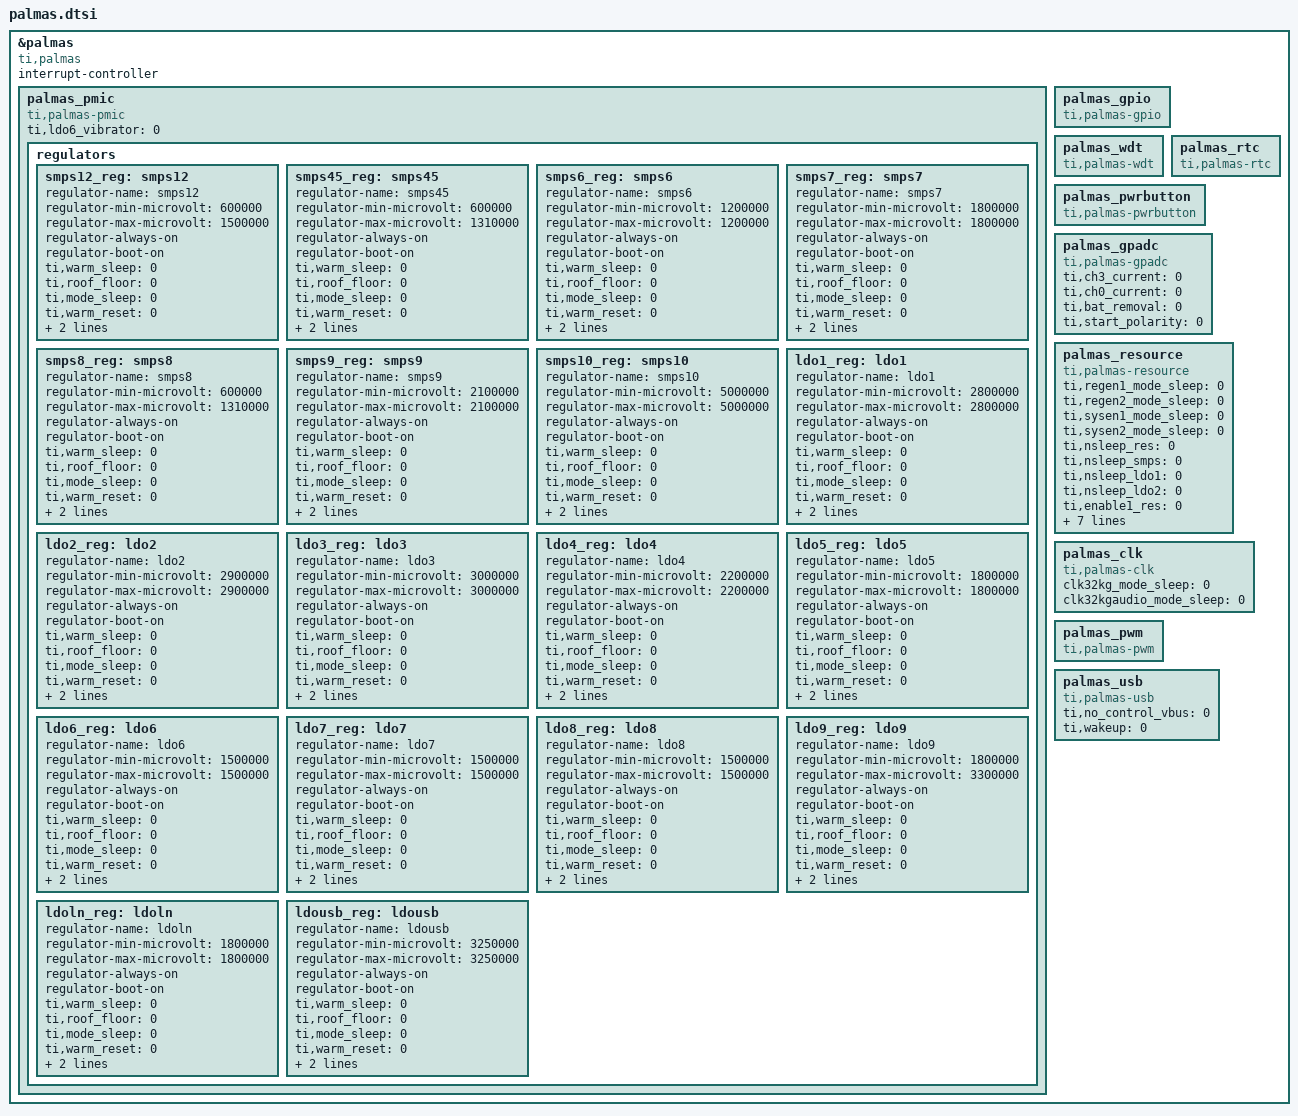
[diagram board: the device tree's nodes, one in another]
&palmas {
	compatible = "ti,palmas";
	interrupt-controller;
	#interrupt-cells = <2>;

	palmas_pmic {
		compatible = "ti,palmas-pmic";
		ti,ldo6_vibrator = <0>;

		regulators {
			smps12_reg: smps12 {
				regulator-name = "smps12";
				regulator-min-microvolt = < 600000>;
				regulator-max-microvolt = <1500000>;
				regulator-always-on;
				regulator-boot-on;
				ti,warm_sleep = <0>;
				ti,roof_floor = <0>;
				ti,mode_sleep = <0>;
				ti,warm_reset = <0>;
				ti,tstep = <0>;
				ti,vsel = <0>;
			};

			smps45_reg: smps45 {
				regulator-name = "smps45";
				regulator-min-microvolt = < 600000>;
				regulator-max-microvolt = <1310000>;
				regulator-always-on;
				regulator-boot-on;
				ti,warm_sleep = <0>;
				ti,roof_floor = <0>;
				ti,mode_sleep = <0>;
				ti,warm_reset = <0>;
				ti,tstep = <0>;
				ti,vsel = <0>;
			};

			smps6_reg: smps6 {
				regulator-name = "smps6";
				regulator-min-microvolt = <1200000>;
				regulator-max-microvolt = <1200000>;
				regulator-always-on;
				regulator-boot-on;
				ti,warm_sleep = <0>;
				ti,roof_floor = <0>;
				ti,mode_sleep = <0>;
				ti,warm_reset = <0>;
				ti,tstep = <0>;
				ti,vsel = <0>;
			};

			smps7_reg: smps7 {
				regulator-name = "smps7";
				regulator-min-microvolt = <1800000>;
				regulator-max-microvolt = <1800000>;
				regulator-always-on;
				regulator-boot-on;
				ti,warm_sleep = <0>;
				ti,roof_floor = <0>;
				ti,mode_sleep = <0>;
				ti,warm_reset = <0>;
				ti,tstep = <0>;
				ti,vsel = <0>;
			};

			smps8_reg: smps8 {
				regulator-name = "smps8";
				regulator-min-microvolt = < 600000>;
				regulator-max-microvolt = <1310000>;
				regulator-always-on;
				regulator-boot-on;
				ti,warm_sleep = <0>;
				ti,roof_floor = <0>;
				ti,mode_sleep = <0>;
				ti,warm_reset = <0>;
				ti,tstep = <0>;
				ti,vsel = <0>;
			};

			smps9_reg: smps9 {
				regulator-name = "smps9";
				regulator-min-microvolt = <2100000>;
				regulator-max-microvolt = <2100000>;
				regulator-always-on;
				regulator-boot-on;
				ti,warm_sleep = <0>;
				ti,roof_floor = <0>;
				ti,mode_sleep = <0>;
				ti,warm_reset = <0>;
				ti,tstep = <0>;
				ti,vsel = <0x80>;
			};

			smps10_reg: smps10 {
				regulator-name = "smps10";
				regulator-min-microvolt = <5000000>;
				regulator-max-microvolt = <5000000>;
				regulator-always-on;
				regulator-boot-on;
				ti,warm_sleep = <0>;
				ti,roof_floor = <0>;
				ti,mode_sleep = <0>;
				ti,warm_reset = <0>;
				ti,tstep = <0>;
				ti,vsel = <0>;
			};

			ldo1_reg: ldo1 {
				regulator-name = "ldo1";
				regulator-min-microvolt = <2800000>;
				regulator-max-microvolt = <2800000>;
				regulator-always-on;
				regulator-boot-on;
				ti,warm_sleep = <0>;
				ti,roof_floor = <0>;
				ti,mode_sleep = <0>;
				ti,warm_reset = <0>;
				ti,tstep = <0>;
				ti,vsel = <0>;
			};

			ldo2_reg: ldo2 {
				regulator-name = "ldo2";
				regulator-min-microvolt = <2900000>;
				regulator-max-microvolt = <2900000>;
				regulator-always-on;
				regulator-boot-on;
				ti,warm_sleep = <0>;
				ti,roof_floor = <0>;
				ti,mode_sleep = <0>;
				ti,warm_reset = <0>;
				ti,tstep = <0>;
				ti,vsel = <0>;
			};

			ldo3_reg: ldo3 {
				regulator-name = "ldo3";
				regulator-min-microvolt = <3000000>;
				regulator-max-microvolt = <3000000>;
				regulator-always-on;
				regulator-boot-on;
				ti,warm_sleep = <0>;
				ti,roof_floor = <0>;
				ti,mode_sleep = <0>;
				ti,warm_reset = <0>;
				ti,tstep = <0>;
				ti,vsel = <0>;
			};

			ldo4_reg: ldo4 {
				regulator-name = "ldo4";
				regulator-min-microvolt = <2200000>;
				regulator-max-microvolt = <2200000>;
				regulator-always-on;
				regulator-boot-on;
				ti,warm_sleep = <0>;
				ti,roof_floor = <0>;
				ti,mode_sleep = <0>;
				ti,warm_reset = <0>;
				ti,tstep = <0>;
				ti,vsel = <0>;
			};

			ldo5_reg: ldo5 {
				regulator-name = "ldo5";
				regulator-min-microvolt = <1800000>;
				regulator-max-microvolt = <1800000>;
				regulator-always-on;
				regulator-boot-on;
				ti,warm_sleep = <0>;
				ti,roof_floor = <0>;
				ti,mode_sleep = <0>;
				ti,warm_reset = <0>;
				ti,tstep = <0>;
				ti,vsel = <0>;
			};

			ldo6_reg: ldo6 {
				regulator-name = "ldo6";
				regulator-min-microvolt = <1500000>;
				regulator-max-microvolt = <1500000>;
				regulator-always-on;
				regulator-boot-on;
				ti,warm_sleep = <0>;
				ti,roof_floor = <0>;
				ti,mode_sleep = <0>;
				ti,warm_reset = <0>;
				ti,tstep = <0>;
				ti,vsel = <0>;
			};

			ldo7_reg: ldo7 {
				regulator-name = "ldo7";
				regulator-min-microvolt = <1500000>;
				regulator-max-microvolt = <1500000>;
				regulator-always-on;
				regulator-boot-on;
				ti,warm_sleep = <0>;
				ti,roof_floor = <0>;
				ti,mode_sleep = <0>;
				ti,warm_reset = <0>;
				ti,tstep = <0>;
				ti,vsel = <0>;
			};

			ldo8_reg: ldo8 {
				regulator-name = "ldo8";
				regulator-min-microvolt = <1500000>;
				regulator-max-microvolt = <1500000>;
				regulator-always-on;
				regulator-boot-on;
				ti,warm_sleep = <0>;
				ti,roof_floor = <0>;
				ti,mode_sleep = <0>;
				ti,warm_reset = <0>;
				ti,tstep = <0>;
				ti,vsel = <0>;
			};

			ldo9_reg: ldo9 {
				regulator-name = "ldo9";
				regulator-min-microvolt = <1800000>;
				regulator-max-microvolt = <3300000>;
				regulator-always-on;
				regulator-boot-on;
				ti,warm_sleep = <0>;
				ti,roof_floor = <0>;
				ti,mode_sleep = <0>;
				ti,warm_reset = <0>;
				ti,tstep = <0>;
				ti,vsel = <0>;
			};

			ldoln_reg: ldoln {
				regulator-name = "ldoln";
				regulator-min-microvolt = <1800000>;
				regulator-max-microvolt = <1800000>;
				regulator-always-on;
				regulator-boot-on;
				ti,warm_sleep = <0>;
				ti,roof_floor = <0>;
				ti,mode_sleep = <0>;
				ti,warm_reset = <0>;
				ti,tstep = <0>;
				ti,vsel = <0>;
			};

			ldousb_reg: ldousb {
				regulator-name = "ldousb";
				regulator-min-microvolt = <3250000>;
				regulator-max-microvolt = <3250000>;
				regulator-always-on;
				regulator-boot-on;
				ti,warm_sleep = <0>;
				ti,roof_floor = <0>;
				ti,mode_sleep = <0>;
				ti,warm_reset = <0>;
				ti,tstep = <0>;
				ti,vsel = <0>;
			};
		};
	};

	palmas_gpio {
		compatible = "ti,palmas-gpio";
	};

	palmas_wdt {
		compatible = "ti,palmas-wdt";
	};

	palmas_rtc {
		compatible = "ti,palmas-rtc";
	};

	palmas_pwrbutton {
		compatible = "ti,palmas-pwrbutton";
	};

	palmas_gpadc {
		compatible = "ti,palmas-gpadc";
		ti,ch3_current = <0>;
		ti,ch0_current = <0>;
		ti,bat_removal = <0>;
		ti,start_polarity = <0>;
	};

	palmas_resource {
		compatible = "ti,palmas-resource";
		ti,regen1_mode_sleep = <0>;
		ti,regen2_mode_sleep = <0>;
		ti,sysen1_mode_sleep = <0>;
		ti,sysen2_mode_sleep = <0>;
		ti,nsleep_res = <0>;
		ti,nsleep_smps = <0>;
		ti,nsleep_ldo1 = <0>;
		ti,nsleep_ldo2 = <0>;
		ti,enable1_res = <0>;
		ti,enable1_smps = <0>;
		ti,enable1_ldo1 = <0>;
		ti,enable1_ldo2 = <0>;
		ti,enable2_res = <0>;
		ti,enable2_smps = <0>;
		ti,enable2_ldo1 = <0>;
		ti,enable2_ldo2 = <0>;
	};

	palmas_clk {
		compatible = "ti,palmas-clk";
		clk32kg_mode_sleep = <0>;
		clk32kgaudio_mode_sleep = <0>;
	};

	palmas_pwm {
		compatible = "ti,palmas-pwm";
	};

	palmas_usb {
		compatible = "ti,palmas-usb";
		ti,no_control_vbus = <0>;
		ti,wakeup = <0>;
	};
};

